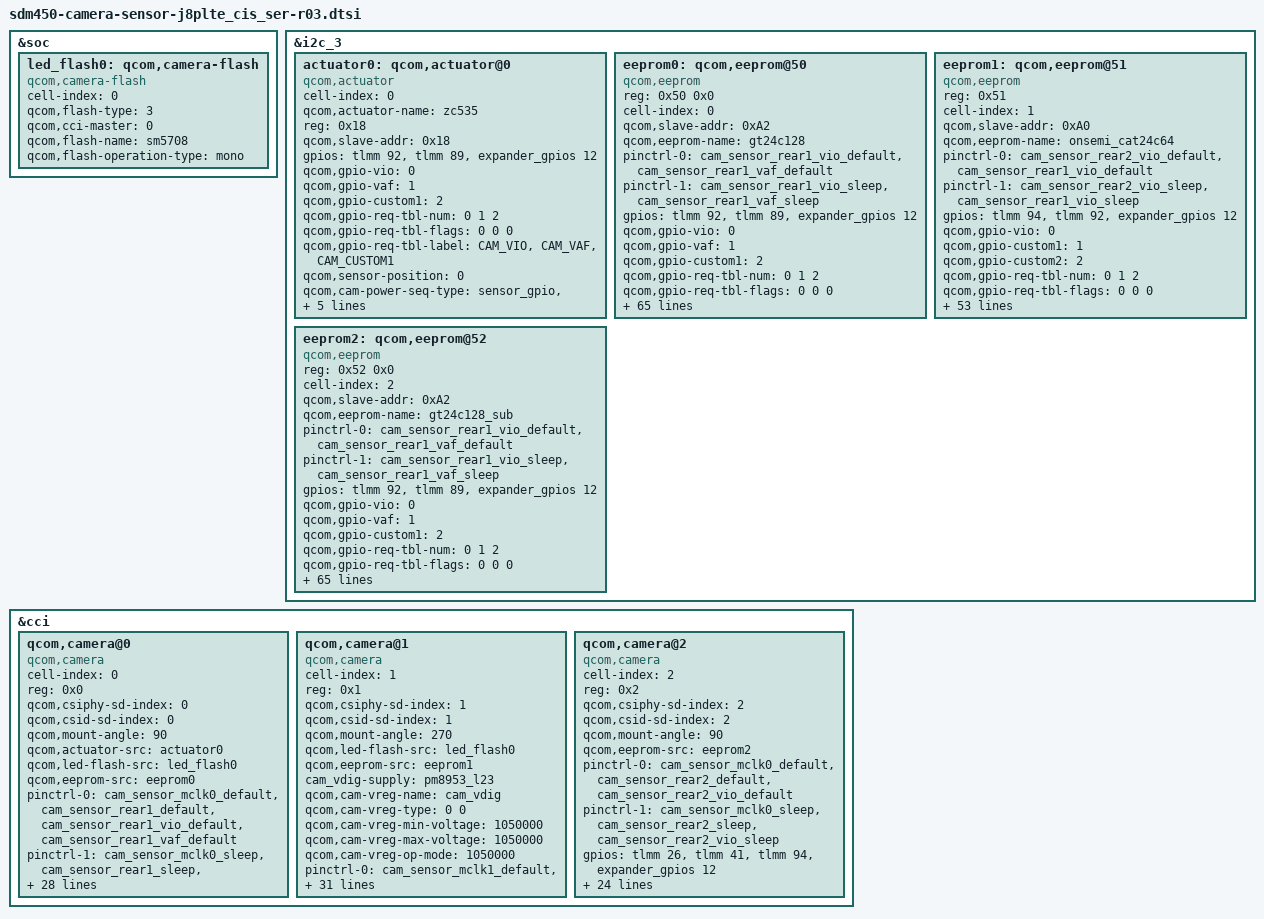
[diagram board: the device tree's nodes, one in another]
/*
 * Copyright (c) 2017, The Linux Foundation. All rights reserved.
 *
 * This program is free software; you can redistribute it and/or modify
 * it under the terms of the GNU General Public License version 2 and
 * only version 2 as published by the Free Software Foundation.
 *
 * This program is distributed in the hope that it will be useful,
 * but WITHOUT ANY WARRANTY; without even the implied warranty of
 * MERCHANTABILITY or FITNESS FOR A PARTICULAR PURPOSE.  See the
 * GNU General Public License for more details.
 */

&soc {	
	led_flash0: qcom,camera-flash {
		cell-index = <0>;
		compatible = "qcom,camera-flash";
		qcom,flash-type = <3>;
		qcom,cci-master = <0>;
		qcom,flash-name = "sm5708";
		qcom,flash-operation-type = "mono";
	};
};

&i2c_3 {
    status = "okay";
    actuator0: qcom,actuator@0 {
		compatible = "qcom,actuator";
		cell-index = <0>;
		qcom,actuator-name = "zc535";
		reg = <0x18>;
		qcom,slave-addr = <0x18>;

		gpios = <&tlmm 92 0>,
		    <&tlmm 89 0>,
		    <&expander_gpios 12 0>;
		qcom,gpio-vio = <0>;		
		qcom,gpio-vaf = <1>;
		qcom,gpio-custom1 = <2>;
		qcom,gpio-req-tbl-num = <0 1 2>;
		qcom,gpio-req-tbl-flags = <0 0 0>;
		qcom,gpio-req-tbl-label = "CAM_VIO","CAM_VAF", "CAM_CUSTOM1";
        qcom,sensor-position = <0>;
		qcom,cam-power-seq-type = "sensor_gpio", "sensor_gpio", "sensor_gpio";
		qcom,cam-power-seq-val = "sensor_gpio_vio", "sensor_gpio_vaf", "sensor_gpio_custom1";
		qcom,cam-power-seq-cfg-val = <1 1 1>;
		qcom,cam-power-seq-delay = <2 2 2>;
	};	

	eeprom0: qcom,eeprom@50 {
		compatible = "qcom,eeprom";
		reg = <0x50 0x0>;
		cell-index = <0>;
		qcom,slave-addr = <0xA2>;
		qcom,eeprom-name = "gt24c128";
		pinctrl-names = "cam_default", "cam_suspend";
		pinctrl-0 = <&cam_sensor_rear1_vio_default
				&cam_sensor_rear1_vaf_default>;
		pinctrl-1 = <&cam_sensor_rear1_vio_sleep
				&cam_sensor_rear1_vaf_sleep>;
		gpios = <&tlmm 92 0>,
			<&tlmm 89 0>,
			<&expander_gpios 12 0>;
		qcom,gpio-vio = <0>;
		qcom,gpio-vaf = <1>;
		qcom,gpio-custom1 = <2>;
		qcom,gpio-req-tbl-num = <0 1 2>;
		qcom,gpio-req-tbl-flags = <0 0 0>;
		qcom,gpio-req-tbl-label = "CAM_VIO", "CAM_VAF", "CAM_CUSTOM1";
		qcom,sensor-position = <0>;		
		qcom,cam-power-seq-type = "sensor_gpio", "sensor_gpio", "sensor_gpio";
		qcom,cam-power-seq-val = "sensor_gpio_vio","sensor_gpio_vaf", "sensor_gpio_custom1";
		qcom,cam-power-seq-cfg-val = <1 1 1>;
		qcom,cam-power-seq-delay = <2 2 2>;		

		qcom,num-blocks = <18>;
		qcom,page0 = <0 0 0 0 0 0>;
		qcom,poll0 = <0 0 0 0 0 0>;
		qcom,mem0 = <0xFC 0x00 2 0 1 0>;

		qcom,page1 = <0 0 0 0 0 0>;
		qcom,poll1 = <0 0 0 0 0 0>;
		qcom,mem1 = <0x4 0xFC 2 0 1 0>;

		qcom,page2 = <0 0 0 0 0 0>;
		qcom,poll2 = <0 0 0 0 0 0>;
		qcom,mem2 = <0x708 0x100 2 0 1 0>;

		qcom,page3 = <0 0 0 0 0 0>;
		qcom,poll3 = <0 0 0 0 0 0>;
		qcom,mem3 = <0x4 0x808 2 0 1 0>; 

		qcom,page4 = <0 0 0 0 0 0>;
		qcom,poll4 = <0 0 0 0 0 0>;
		qcom,mem4 = <0x50 0x80C 2 0 1 0>; 

		qcom,page5 = <0 0 0 0 0 0>;
		qcom,poll5 = <0 0 0 0 0 0>;
		qcom,mem5 = <0x4 0x85C 2 0 1 0>;

		qcom,page6 = <0 0 0 0 0 0>;
		qcom,poll6 = <0 0 0 0 0 0>;
		qcom,mem6 = <0x30 0x860 2 0 1 0>; 

		qcom,page7 = <0 0 0 0 0 0>;
		qcom,poll7 = <0 0 0 0 0 0>;
		qcom,mem7 = <0x4 0x890 2 0 1 0>; 	

		qcom,page8 = <0 0 0 0 0 0>;
		qcom,poll8 = <0 0 0 0 0 0>;
		qcom,mem8 = <0x38 0x894 2 0 1 0>; 

		qcom,page9 = <0 0 0 0 0 0>;
		qcom,poll9 = <0 0 0 0 0 0>;
		qcom,mem9 = <0x4 0x8CC 2 0 1 0>; 

		qcom,page10 = <0 0 0 0 0 0>;
		qcom,poll10 = <0 0 0 0 0 0>;
		qcom,mem10 = <0x708 0x900 2 0 1 0>; 

		qcom,page11 = <0 0 0 0 0 0>;
		qcom,poll11 = <0 0 0 0 0 0>;
		qcom,mem11 = <0x4 0x1008 2 0 1 0>; 

		qcom,page12 = <0 0 0 0 0 0>;
		qcom,poll12 = <0 0 0 0 0 0>;
		qcom,mem12 = <0x30 0x1060 2 0 1 0>; 

		qcom,page13 = <0 0 0 0 0 0>;
		qcom,poll13 = <0 0 0 0 0 0>;
		qcom,mem13 = <0x4 0x1090 2 0 1 0>; 

		qcom,page14 = <0 0 0 0 0 0>;
		qcom,poll14 = <0 0 0 0 0 0>;
		qcom,mem14 = <0x48 0x1094 2 0 1 0>; 

		qcom,page15 = <0 0 0 0 0 0>;
		qcom,poll15 = <0 0 0 0 0 0>;
		qcom,mem15 = <0x4 0x10DC 2 0 1 0>; 

		qcom,page16 = <0 0 0 0 0 0>;
		qcom,poll16 = <0 0 0 0 0 0>;
		qcom,mem16 = <0x80C 0x10E0 2 0 1 0>; 

		qcom,page17 = <0 0 0 0 0 0>;
		qcom,poll17 = <0 0 0 0 0 0>;
		qcom,mem17 = <0x4 0x18EC 2 0 1 0>; 	

		qcom,total-size = <0x1900>;
	};

	eeprom1: qcom,eeprom@51 {
		compatible = "qcom,eeprom";
	        reg = <0x51>;
	        cell-index = <1>;
		qcom,slave-addr = <0xA0>;
		qcom,eeprom-name = "onsemi_cat24c64";	
		pinctrl-names = "cam_default", "cam_suspend";
		pinctrl-0 = <&cam_sensor_rear2_vio_default
		        &cam_sensor_rear1_vio_default>;
		pinctrl-1 = <&cam_sensor_rear2_vio_sleep
		        &cam_sensor_rear1_vio_sleep>;
		gpios = <&tlmm 94 0>,
		    <&tlmm 92 0>,
		    <&expander_gpios 12 0>;		
		qcom,gpio-vio = <0>;
		qcom,gpio-custom1 = <1>;
		qcom,gpio-custom2 = <2>;
		qcom,gpio-req-tbl-num = <0 1 2>;
		qcom,gpio-req-tbl-flags = <0 0 0>;
		qcom,gpio-req-tbl-label = "CAM_CUSTOM1", "CAM_CUSTOM2", "CAM_VIO";
		qcom,sensor-position = <1>;
		qcom,cam-power-seq-type = "sensor_gpio", "sensor_gpio", "sensor_gpio";
		qcom,cam-power-seq-val = "sensor_gpio_custom1", "sensor_gpio_custom2", "sensor_gpio_vio";
		qcom,cam-power-seq-cfg-val = <1 1 1>;
		qcom,cam-power-seq-delay = <2 2 2>;
			
		qcom,num-blocks = <14>;
		qcom,page0 = <0 0 0 0 0 0>;
		qcom,poll0 = <0 0 0 0 0 0>;
		qcom,mem0 = <0xE8 0x00 2 0 1 0>;

		qcom,page1 = <0 0 0 0 0 0>;
		qcom,poll1 = <0 0 0 0 0 0>;
		qcom,mem1 = <0x4 0xE8 2 0 1 0>;

		qcom,page2 = <0 0 0 0 0 0>;
		qcom,poll2 = <0 0 0 0 0 0>;
		qcom,mem2 = <0x708 0xEC 2 0 1 0>;

		qcom,page3 = <0 0 0 0 0 0>;
		qcom,poll3 = <0 0 0 0 0 0>;
		qcom,mem3 = <0x4 0x7F4 2 0 1 0>; 

		qcom,page4 = <0 0 0 0 0 0>;
		qcom,poll4 = <0 0 0 0 0 0>;
		qcom,mem4 = <0x50 0x7F8 2 0 1 0>; 

		qcom,page5 = <0 0 0 0 0 0>;
		qcom,poll5 = <0 0 0 0 0 0>;
		qcom,mem5 = <0x4 0x848 2 0 1 0>;

		qcom,page6 = <0 0 0 0 0 0>;
		qcom,poll6 = <0 0 0 0 0 0>;
		qcom,mem6 = <0x30 0x84C 2 0 1 0>; 

		qcom,page7 = <0 0 0 0 0 0>;
		qcom,poll7 = <0 0 0 0 0 0>;
		qcom,mem7 = <0x4 0x87C 2 0 1 0>; 	

		qcom,page8 = <0 0 0 0 0 0>;
		qcom,poll8 = <0 0 0 0 0 0>;
		qcom,mem8 = <0x24 0x880 2 0 1 0>; 

		qcom,page9 = <0 0 0 0 0 0>;
		qcom,poll9 = <0 0 0 0 0 0>;
		qcom,mem9 = <0x4 0x8A4 2 0 1 0>; 

		qcom,page10 = <0 0 0 0 0 0>;
		qcom,poll10 = <0 0 0 0 0 0>;
		qcom,mem10 = <0x6A 0x8A8 2 0 1 0>; 

		qcom,page11 = <0 0 0 0 0 0>;
		qcom,poll11 = <0 0 0 0 0 0>;
		qcom,mem11 = <0x0 0x0 2 0 1 0>; 

		qcom,page12 = <0 0 0 0 0 0>;
		qcom,poll12 = <0 0 0 0 0 0>;
		qcom,mem12 = <0xCFC 0x916 2 0 1 0>; 

		qcom,page13 = <0 0 0 0 0 0>;
		qcom,poll13 = <0 0 0 0 0 0>;
		qcom,mem13 = <0x4 0x1612 2 0 1 0>;  

		qcom,total-size = <0x1616>;
	}; 

	eeprom2: qcom,eeprom@52 {
		compatible = "qcom,eeprom";
		reg = <0x52 0x0>;
		cell-index = <2>;
		qcom,slave-addr = <0xA2>;
		qcom,eeprom-name = "gt24c128_sub";
		pinctrl-names = "cam_default", "cam_suspend";
		pinctrl-0 = <&cam_sensor_rear1_vio_default
				&cam_sensor_rear1_vaf_default>;
		pinctrl-1 = <&cam_sensor_rear1_vio_sleep
				&cam_sensor_rear1_vaf_sleep>;
		gpios = <&tlmm 92 0>,
			<&tlmm 89 0>,
			<&expander_gpios 12 0>;
		qcom,gpio-vio = <0>;
		qcom,gpio-vaf = <1>;
		qcom,gpio-custom1 = <2>;
		qcom,gpio-req-tbl-num = <0 1 2>;
		qcom,gpio-req-tbl-flags = <0 0 0>;
		qcom,gpio-req-tbl-label = "CAM_VIO", "CAM_VAF", "CAM_CUSTOM1";
		qcom,sensor-position = <0>;		
		qcom,cam-power-seq-type = "sensor_gpio", "sensor_gpio", "sensor_gpio";
		qcom,cam-power-seq-val = "sensor_gpio_vio","sensor_gpio_vaf", "sensor_gpio_custom1";
		qcom,cam-power-seq-cfg-val = <1 1 1>;
		qcom,cam-power-seq-delay = <2 2 2>;		

		qcom,num-blocks = <18>;
		qcom,page0 = <0 0 0 0 0 0>;
		qcom,poll0 = <0 0 0 0 0 0>;
		qcom,mem0 = <0xFC 0x00 2 0 1 0>;

		qcom,page1 = <0 0 0 0 0 0>;
		qcom,poll1 = <0 0 0 0 0 0>;
		qcom,mem1 = <0x4 0xFC 2 0 1 0>;

		qcom,page2 = <0 0 0 0 0 0>;
		qcom,poll2 = <0 0 0 0 0 0>;
		qcom,mem2 = <0x708 0x100 2 0 1 0>;

		qcom,page3 = <0 0 0 0 0 0>;
		qcom,poll3 = <0 0 0 0 0 0>;
		qcom,mem3 = <0x4 0x808 2 0 1 0>; 

		qcom,page4 = <0 0 0 0 0 0>;
		qcom,poll4 = <0 0 0 0 0 0>;
		qcom,mem4 = <0x50 0x80C 2 0 1 0>; 

		qcom,page5 = <0 0 0 0 0 0>;
		qcom,poll5 = <0 0 0 0 0 0>;
		qcom,mem5 = <0x4 0x85C 2 0 1 0>;

		qcom,page6 = <0 0 0 0 0 0>;
		qcom,poll6 = <0 0 0 0 0 0>;
		qcom,mem6 = <0x30 0x860 2 0 1 0>; 

		qcom,page7 = <0 0 0 0 0 0>;
		qcom,poll7 = <0 0 0 0 0 0>;
		qcom,mem7 = <0x4 0x890 2 0 1 0>; 	

		qcom,page8 = <0 0 0 0 0 0>;
		qcom,poll8 = <0 0 0 0 0 0>;
		qcom,mem8 = <0x38 0x894 2 0 1 0>; 

		qcom,page9 = <0 0 0 0 0 0>;
		qcom,poll9 = <0 0 0 0 0 0>;
		qcom,mem9 = <0x4 0x8CC 2 0 1 0>; 

		qcom,page10 = <0 0 0 0 0 0>;
		qcom,poll10 = <0 0 0 0 0 0>;
		qcom,mem10 = <0x708 0x900 2 0 1 0>; 

		qcom,page11 = <0 0 0 0 0 0>;
		qcom,poll11 = <0 0 0 0 0 0>;
		qcom,mem11 = <0x4 0x1008 2 0 1 0>; 

		qcom,page12 = <0 0 0 0 0 0>;
		qcom,poll12 = <0 0 0 0 0 0>;
		qcom,mem12 = <0x30 0x1060 2 0 1 0>; 

		qcom,page13 = <0 0 0 0 0 0>;
		qcom,poll13 = <0 0 0 0 0 0>;
		qcom,mem13 = <0x4 0x1090 2 0 1 0>; 

		qcom,page14 = <0 0 0 0 0 0>;
		qcom,poll14 = <0 0 0 0 0 0>;
		qcom,mem14 = <0x48 0x1094 2 0 1 0>; 

		qcom,page15 = <0 0 0 0 0 0>;
		qcom,poll15 = <0 0 0 0 0 0>;
		qcom,mem15 = <0x4 0x10DC 2 0 1 0>; 

		qcom,page16 = <0 0 0 0 0 0>;
		qcom,poll16 = <0 0 0 0 0 0>;
		qcom,mem16 = <0x80C 0x10E0 2 0 1 0>; 

		qcom,page17 = <0 0 0 0 0 0>;
		qcom,poll17 = <0 0 0 0 0 0>;
		qcom,mem17 = <0x4 0x18EC 2 0 1 0>; 	

		qcom,total-size = <0x1900>;
	}; 
	
};

&cci {
	qcom,camera@0 {
		// REAR MAIN
		cell-index = <0>;
		compatible = "qcom,camera";
		reg = <0x0>;
		qcom,csiphy-sd-index = <0>;
		qcom,csid-sd-index = <0>;
		qcom,mount-angle = <90>;
		qcom,actuator-src = <&actuator0>;
		qcom,led-flash-src = <&led_flash0>;
		qcom,eeprom-src = <&eeprom0>;

		pinctrl-names = "cam_default", "cam_suspend";
		pinctrl-0 = <&cam_sensor_mclk0_default
				&cam_sensor_rear1_default
				&cam_sensor_rear1_vio_default
				&cam_sensor_rear1_vaf_default>;
		pinctrl-1 = <&cam_sensor_mclk0_sleep
				&cam_sensor_rear1_sleep
				&cam_sensor_rear1_vio_sleep
				&cam_sensor_rear1_vaf_sleep>;
		gpios = <&tlmm 26 0>,
			<&tlmm 40 0>,
			<&tlmm 92 0>,
			<&tlmm 89 0>,
			<&expander_gpios 12 0>;
		qcom,gpio-reset = <1>;
		qcom,gpio-vio = <2>;
		qcom,gpio-vaf = <3>;
		qcom,gpio-custom1 = <4>;
		qcom,gpio-req-tbl-num = <0 1 2 3 4>;
		qcom,gpio-req-tbl-flags = <1 0 0 0 0>;
		qcom,gpio-req-tbl-label = "CAMIF_MCLK0", "CAM_RESET0", "CAM_VIO", "CAM_VAF", "CAM_CUSTOM1";
		qcom,sensor-position = <0>;
		qcom,sensor-mode = <0>;
		qcom,cci-master = <1>;
		status = "ok";
		clocks = <&clock_gcc clk_mclk0_clk_src>,
				<&clock_gcc clk_gcc_camss_mclk0_clk>;
		clock-names = "cam_src_clk", "cam_clk";
		qcom,clock-rates = <24000000 0>;
		cam,isp = <0>;                  // 0 : INT , 1 : EXT , 2 : SOC
		cam,cal_memory = <2>;           // 0 : N , 1 : FROM , 2 : EEPROM , 3 : OTP
		cam,read_version = <0>;         // 0 : SYSFS , 1 : CAMON
		cam,core_voltage = <0>;         // 0 : N , 1 : Y
		cam,upgrade = <0>;              // 0 : N , 1 : SYSFS , 2 : CAMON
		cam,fw_write = <0>;             // 0 : N , 1 : OS , 2 : SD , 3 : ALL
		cam,fw_dump = <0>;              // 0 : N , 1 : Y
		cam,companion_chip = <0>;       // 0 : N , 1 : Y
		cam,ois = <0>;                  // 0 : N , 1 : Y
		cam,valid = <1>;                // 0 : N , 1 : Y
	};
	qcom,camera@1 {
		// FRONT CAMERA
		cell-index = <1>;
		compatible = "qcom,camera";
		reg = <0x1>;
		qcom,csiphy-sd-index = <1>;
		qcom,csid-sd-index = <1>;
		qcom,mount-angle = <270>;
		qcom,led-flash-src = <&led_flash0>;
		qcom,eeprom-src = <&eeprom1>;

		cam_vdig-supply = <&pm8953_l23>;
		qcom,cam-vreg-name = "cam_vdig";
		qcom,cam-vreg-type = <0 0>;
		qcom,cam-vreg-min-voltage = <1050000>;
		qcom,cam-vreg-max-voltage = <1050000>;
		qcom,cam-vreg-op-mode = <1050000>;

		pinctrl-names = "cam_default", "cam_suspend";
		pinctrl-0 = <&cam_sensor_mclk1_default
				&cam_sensor_front_default
				&cam_sensor_rear2_vio_default>;
		pinctrl-1 = <&cam_sensor_mclk1_sleep
				&cam_sensor_front_sleep		
				&cam_sensor_rear2_vio_sleep>;
		gpios = <&tlmm 27 0>,
			<&tlmm 129 0>,
			<&expander_gpios 12 0>,
			<&expander_gpios 13 0>,
			<&tlmm 94 0>;
		qcom,gpio-reset = <1>;
		qcom,gpio-vio = <2>;
		qcom,gpio-vana = <3>;
		qcom,gpio-custom1 = <4>;
		qcom,gpio-req-tbl-num = <0 1 2 3 4>;
		qcom,gpio-req-tbl-flags = <1 0 0 0 0>;
		qcom,gpio-req-tbl-label = "CAMIF_MCLK1", "CAM_RESET1", "CAM_VIO", "CAM_VANA", "CAM_CUSTOM1";
		qcom,sensor-position = <1>;
		qcom,sensor-mode = <0>;
		qcom,cci-master = <0>;
		status = "ok";
		clocks = <&clock_gcc clk_mclk1_clk_src>,
				<&clock_gcc clk_gcc_camss_mclk1_clk>;
		clock-names = "cam_src_clk", "cam_clk";
		qcom,clock-rates = <24000000 0>;
		cam,isp = <0>;                  // 0 : INT , 1 : EXT , 2 : SOC
		cam,cal_memory = <2>;           // 0 : N , 1 : FROM , 2 : EEPROM , 3 : OTP
		cam,read_version = <0>;         // 0 : SYSFS , 1 : CAMON
		cam,core_voltage = <0>;         // 0 : N , 1 : Y
		cam,upgrade = <0>;              // 0 : N , 1 : SYSFS , 2 : CAMON
		cam,fw_write = <0>;             // 0 : N , 1 : OS , 2 : SD , 3 : ALL
		cam,fw_dump = <0>;              // 0 : N , 1 : Y
		cam,companion_chip = <0>;       // 0 : N , 1 : Y
		cam,ois = <0>;                  // 0 : N , 1 : Y
		cam,valid = <1>;                // 0 : N , 1 : Y
	};
	qcom,camera@2 {
		// REAR SUB
		cell-index = <2>;
		compatible = "qcom,camera";
		reg = <0x2>;
		qcom,csiphy-sd-index = <2>;
		qcom,csid-sd-index = <2>;
		qcom,mount-angle = <90>;
		qcom,eeprom-src = <&eeprom2>;
		pinctrl-names = "cam_default", "cam_suspend";
		pinctrl-0 = <&cam_sensor_mclk0_default
				&cam_sensor_rear2_default
				&cam_sensor_rear2_vio_default>;
		pinctrl-1 = <&cam_sensor_mclk0_sleep
				&cam_sensor_rear2_sleep
				&cam_sensor_rear2_vio_sleep>;
		gpios = <&tlmm 26 0>,
			<&tlmm 41 0>,
			<&tlmm 94 0>,
			<&expander_gpios 12 0>;
		qcom,gpio-reset = <1>;
		qcom,gpio-vio = <2>;
		qcom,gpio-custom1 = <3>;
		qcom,gpio-req-tbl-num = <0 1 2 3>;
		qcom,gpio-req-tbl-flags = <1 0 0 0>;
		qcom,gpio-req-tbl-label = "CAMIF_MCLK0", "CAM_RESET2", "CAM_VIO", "CAM_CUSTOM1";
		qcom,sensor-position = <0>;
		qcom,sensor-mode = <0>;
		qcom,cci-master = <0>;
		status = "ok";
		clocks = <&clock_gcc clk_mclk0_clk_src>,
				<&clock_gcc clk_gcc_camss_mclk0_clk>;
		clock-names = "cam_src_clk", "cam_clk";
		qcom,clock-rates = <24000000 0>;
		cam,isp = <0>;                  // 0 : INT , 1 : EXT , 2 : SOC
		cam,cal_memory = <2>;           // 0 : N , 1 : FROM , 2 : EEPROM , 3 : OTP
		cam,read_version = <0>;         // 0 : SYSFS , 1 : CAMON
		cam,core_voltage = <0>;         // 0 : N , 1 : Y
		cam,upgrade = <0>;              // 0 : N , 1 : SYSFS , 2 : CAMON
		cam,fw_write = <0>;             // 0 : N , 1 : OS , 2 : SD , 3 : ALL
		cam,fw_dump = <0>;              // 0 : N , 1 : Y
		cam,companion_chip = <0>;       // 0 : N , 1 : Y
		cam,ois = <0>;                  // 0 : N , 1 : Y
		cam,valid = <1>;                // 0 : N , 1 : Y
		cam,dual_open = <1>;            // 0 : N , 1 : Y
	};
};

